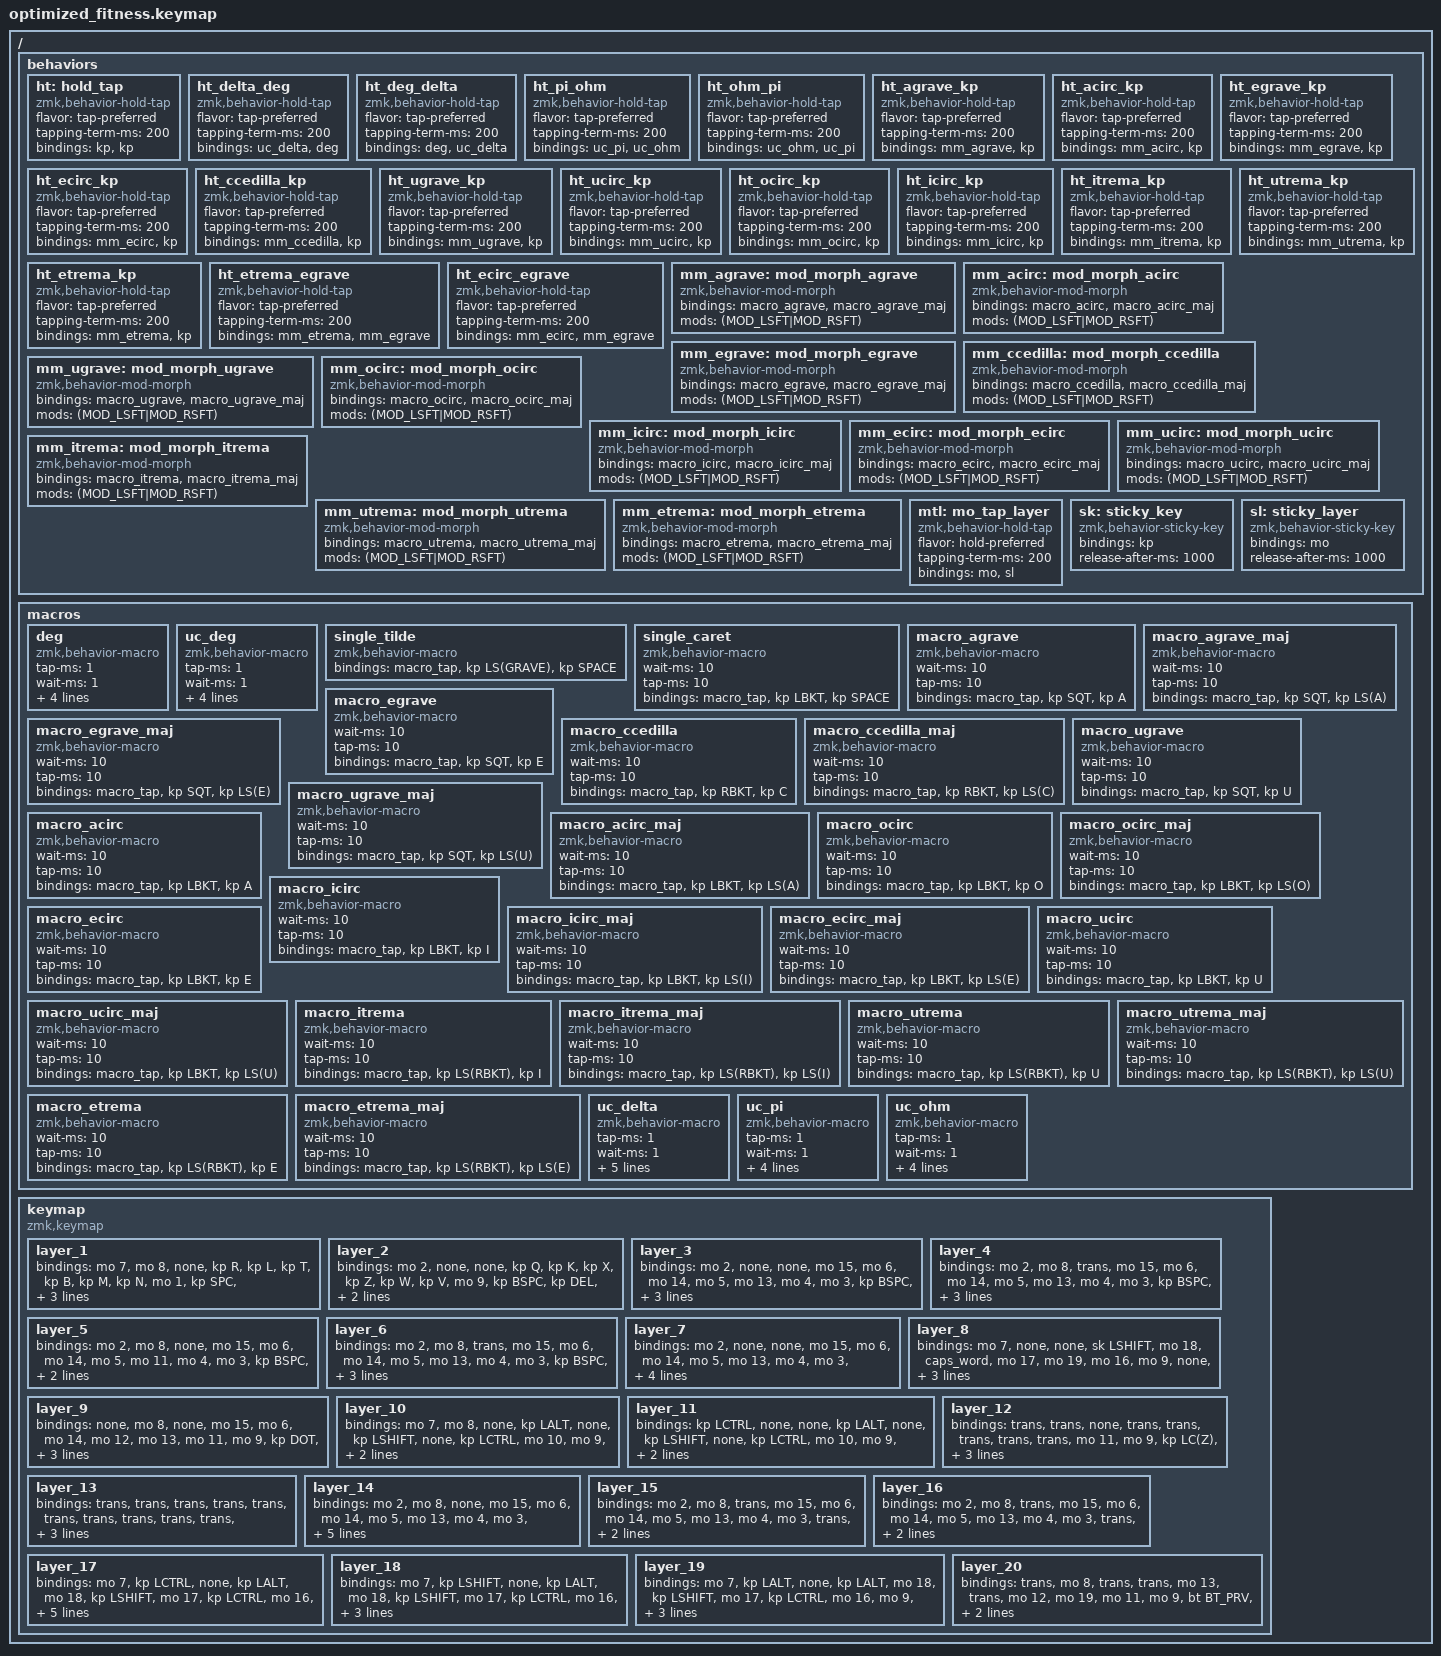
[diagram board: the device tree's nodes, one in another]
#include <behaviors.dtsi>
#include <dt-bindings/zmk/keys.h>
#include <dt-bindings/zmk/bt.h>
#include <dt-bindings/zmk/outputs.h>
#include <dt-bindings/zmk/modifiers.h>

#define DEGREE RA(NUBS)
#define EACUTE FSLH
#define CONTEXTMENU K_APP

/ {
    behaviors {
        ht: hold_tap {
            compatible = "zmk,behavior-hold-tap";
            #binding-cells = <2>;
            flavor = "tap-preferred";
            tapping-term-ms = <200>;
            bindings = <&kp &kp>;
        };

        ht_delta_deg: ht_delta_deg {
            compatible = "zmk,behavior-hold-tap";
            #binding-cells = <2>;
            flavor = "tap-preferred";
            tapping-term-ms = <200>;
            bindings = <&uc_delta &deg>;
        };

        ht_deg_delta: ht_deg_delta {
            compatible = "zmk,behavior-hold-tap";
            #binding-cells = <2>;
            flavor = "tap-preferred";
            tapping-term-ms = <200>;
            bindings = <&deg &uc_delta>;
        };

        ht_pi_ohm: ht_pi_ohm {
            compatible = "zmk,behavior-hold-tap";
            #binding-cells = <2>;
            flavor = "tap-preferred";
            tapping-term-ms = <200>;
            bindings = <&uc_pi &uc_ohm>;
        };

        ht_ohm_pi: ht_ohm_pi {
            compatible = "zmk,behavior-hold-tap";
            #binding-cells = <2>;
            flavor = "tap-preferred";
            tapping-term-ms = <200>;
            bindings = <&uc_ohm &uc_pi>;
        };

        ht_agrave_kp: ht_agrave_kp {
            compatible = "zmk,behavior-hold-tap";
            #binding-cells = <2>;
            flavor = "tap-preferred";
            tapping-term-ms = <200>;
            bindings = <&mm_agrave &kp>;
        };

        ht_acirc_kp: ht_acirc_kp {
            compatible = "zmk,behavior-hold-tap";
            #binding-cells = <2>;
            flavor = "tap-preferred";
            tapping-term-ms = <200>;
            bindings = <&mm_acirc &kp>;
        };

        ht_egrave_kp: ht_egrave_kp {
            compatible = "zmk,behavior-hold-tap";
            #binding-cells = <2>;
            flavor = "tap-preferred";
            tapping-term-ms = <200>;
            bindings = <&mm_egrave &kp>;
        };

        ht_ecirc_kp: ht_ecirc_kp {
            compatible = "zmk,behavior-hold-tap";
            #binding-cells = <2>;
            flavor = "tap-preferred";
            tapping-term-ms = <200>;
            bindings = <&mm_ecirc &kp>;
        };

        ht_ccedilla_kp: ht_ccedilla_kp {
            compatible = "zmk,behavior-hold-tap";
            #binding-cells = <2>;
            flavor = "tap-preferred";
            tapping-term-ms = <200>;
            bindings = <&mm_ccedilla &kp>;
        };

        ht_ugrave_kp: ht_ugrave_kp {
            compatible = "zmk,behavior-hold-tap";
            #binding-cells = <2>;
            flavor = "tap-preferred";
            tapping-term-ms = <200>;
            bindings = <&mm_ugrave &kp>;
        };

        ht_ucirc_kp: ht_ucirc_kp {
            compatible = "zmk,behavior-hold-tap";
            #binding-cells = <2>;
            flavor = "tap-preferred";
            tapping-term-ms = <200>;
            bindings = <&mm_ucirc &kp>;
        };

        ht_ocirc_kp: ht_ocirc_kp {
            compatible = "zmk,behavior-hold-tap";
            #binding-cells = <2>;
            flavor = "tap-preferred";
            tapping-term-ms = <200>;
            bindings = <&mm_ocirc &kp>;
        };

        ht_icirc_kp: ht_icirc_kp {
            compatible = "zmk,behavior-hold-tap";
            #binding-cells = <2>;
            flavor = "tap-preferred";
            tapping-term-ms = <200>;
            bindings = <&mm_icirc &kp>;
        };

        ht_itrema_kp: ht_itrema_kp {
            compatible = "zmk,behavior-hold-tap";
            #binding-cells = <2>;
            flavor = "tap-preferred";
            tapping-term-ms = <200>;
            bindings = <&mm_itrema &kp>;
        };

        ht_utrema_kp: ht_utrema_kp {
            compatible = "zmk,behavior-hold-tap";
            #binding-cells = <2>;
            flavor = "tap-preferred";
            tapping-term-ms = <200>;
            bindings = <&mm_utrema &kp>;
        };

        ht_etrema_kp: ht_etrema_kp {
            compatible = "zmk,behavior-hold-tap";
            #binding-cells = <2>;
            flavor = "tap-preferred";
            tapping-term-ms = <200>;
            bindings = <&mm_etrema &kp>;
        };

        ht_etrema_egrave: ht_etrema_egrave {
            compatible = "zmk,behavior-hold-tap";
            #binding-cells = <2>;
            flavor = "tap-preferred";
            tapping-term-ms = <200>;
            bindings = <&mm_etrema &mm_egrave>;
        };

        ht_ecirc_egrave: ht_ecirc_egrave {
            compatible = "zmk,behavior-hold-tap";
            #binding-cells = <2>;
            flavor = "tap-preferred";
            tapping-term-ms = <200>;
            bindings = <&mm_ecirc &mm_egrave>;
        };

        mm_agrave: mod_morph_agrave {
            compatible = "zmk,behavior-mod-morph";
            #binding-cells = <0>;
            bindings = <&macro_agrave>, <&macro_agrave_maj>;
            mods = <(MOD_LSFT|MOD_RSFT)>;
        };

        mm_acirc: mod_morph_acirc {
            compatible = "zmk,behavior-mod-morph";
            #binding-cells = <0>;
            bindings = <&macro_acirc>, <&macro_acirc_maj>;
            mods = <(MOD_LSFT|MOD_RSFT)>;
        };

        mm_egrave: mod_morph_egrave {
            compatible = "zmk,behavior-mod-morph";
            #binding-cells = <0>;
            bindings = <&macro_egrave>, <&macro_egrave_maj>;
            mods = <(MOD_LSFT|MOD_RSFT)>;
        };

        mm_ccedilla: mod_morph_ccedilla {
            compatible = "zmk,behavior-mod-morph";
            #binding-cells = <0>;
            bindings = <&macro_ccedilla>, <&macro_ccedilla_maj>;
            mods = <(MOD_LSFT|MOD_RSFT)>;
        };

        mm_ugrave: mod_morph_ugrave {
            compatible = "zmk,behavior-mod-morph";
            #binding-cells = <0>;
            bindings = <&macro_ugrave>, <&macro_ugrave_maj>;
            mods = <(MOD_LSFT|MOD_RSFT)>;
        };

        mm_ocirc: mod_morph_ocirc {
            compatible = "zmk,behavior-mod-morph";
            #binding-cells = <0>;
            bindings = <&macro_ocirc>, <&macro_ocirc_maj>;
            mods = <(MOD_LSFT|MOD_RSFT)>;
        };

        mm_icirc: mod_morph_icirc {
            compatible = "zmk,behavior-mod-morph";
            #binding-cells = <0>;
            bindings = <&macro_icirc>, <&macro_icirc_maj>;
            mods = <(MOD_LSFT|MOD_RSFT)>;
        };

        mm_ecirc: mod_morph_ecirc {
            compatible = "zmk,behavior-mod-morph";
            #binding-cells = <0>;
            bindings = <&macro_ecirc>, <&macro_ecirc_maj>;
            mods = <(MOD_LSFT|MOD_RSFT)>;
        };

        mm_ucirc: mod_morph_ucirc {
            compatible = "zmk,behavior-mod-morph";
            #binding-cells = <0>;
            bindings = <&macro_ucirc>, <&macro_ucirc_maj>;
            mods = <(MOD_LSFT|MOD_RSFT)>;
        };

        mm_itrema: mod_morph_itrema {
            compatible = "zmk,behavior-mod-morph";
            #binding-cells = <0>;
            bindings = <&macro_itrema>, <&macro_itrema_maj>;
            mods = <(MOD_LSFT|MOD_RSFT)>;
        };

        mm_utrema: mod_morph_utrema {
            compatible = "zmk,behavior-mod-morph";
            #binding-cells = <0>;
            bindings = <&macro_utrema>, <&macro_utrema_maj>;
            mods = <(MOD_LSFT|MOD_RSFT)>;
        };

        mm_etrema: mod_morph_etrema {
            compatible = "zmk,behavior-mod-morph";
            #binding-cells = <0>;
            bindings = <&macro_etrema>, <&macro_etrema_maj>;
            mods = <(MOD_LSFT|MOD_RSFT)>;
        };

        mtl: mo_tap_layer {
            compatible = "zmk,behavior-hold-tap";
            #binding-cells = <2>;
            flavor = "hold-preferred";
            tapping-term-ms = <200>;
            bindings = <&mo &sl>;
        };

        sk: sticky_key {
            compatible = "zmk,behavior-sticky-key";
            #binding-cells = <1>;
            bindings = <&kp>;
            release-after-ms = <1000>;
        };

        sl: sticky_layer {
            compatible = "zmk,behavior-sticky-key";
            #binding-cells = <1>;
            bindings = <&mo>;
            release-after-ms = <1000>;
        };
    };

    macros {
        deg: deg {
            compatible = "zmk,behavior-macro";
            #binding-cells = <0>;
            tap-ms = <1>;
            wait-ms = <1>;
            bindings = <&macro_press &kp LCTRL &kp LSHFT>
                     , <&macro_tap &kp U>
                     , <&macro_release &kp LCTRL &kp LSHFT>
                     , <&macro_tap &kp NUMBER_0 &kp NUMBER_0 &kp B &kp NUMBER_0 &kp RET>;
        };

        uc_deg: uc_deg {
            compatible = "zmk,behavior-macro";
            #binding-cells = <0>;
            tap-ms = <1>;
            wait-ms = <1>;
            bindings = <&macro_press &kp LCTRL &kp LSHFT>
                     , <&macro_tap &kp U>
                     , <&macro_release &kp LCTRL &kp LSHFT>
                     , <&macro_tap &kp NUMBER_0 &kp NUMBER_0 &kp B &kp NUMBER_0 &kp RET>;
        };

        single_tilde: single_tilde {
            compatible = "zmk,behavior-macro";
            #binding-cells = <0>;
            bindings = <&macro_tap &kp LS(GRAVE) &kp SPACE>;
        };

        single_caret: single_caret {
            compatible = "zmk,behavior-macro";
            #binding-cells = <0>;
            wait-ms = <10>;
            tap-ms = <10>;
            bindings = <&macro_tap &kp LBKT &kp SPACE>;
        };

        macro_agrave: macro_agrave {
            compatible = "zmk,behavior-macro";
            #binding-cells = <0>;
            wait-ms = <10>;
            tap-ms = <10>;
            bindings = <&macro_tap &kp SQT &kp A>;
        };

        macro_agrave_maj: macro_agrave_maj {
            compatible = "zmk,behavior-macro";
            #binding-cells = <0>;
            wait-ms = <10>;
            tap-ms = <10>;
            bindings = <&macro_tap &kp SQT &kp LS(A)>;
        };

        macro_egrave: macro_egrave {
            compatible = "zmk,behavior-macro";
            #binding-cells = <0>;
            wait-ms = <10>;
            tap-ms = <10>;
            bindings = <&macro_tap &kp SQT &kp E>;
        };

        macro_egrave_maj: macro_egrave_maj {
            compatible = "zmk,behavior-macro";
            #binding-cells = <0>;
            wait-ms = <10>;
            tap-ms = <10>;
            bindings = <&macro_tap &kp SQT &kp LS(E)>;
        };

        macro_ccedilla: macro_ccedilla {
            compatible = "zmk,behavior-macro";
            #binding-cells = <0>;
            wait-ms = <10>;
            tap-ms = <10>;
            bindings = <&macro_tap &kp RBKT &kp C>;
        };

        macro_ccedilla_maj: macro_ccedilla_maj {
            compatible = "zmk,behavior-macro";
            #binding-cells = <0>;
            wait-ms = <10>;
            tap-ms = <10>;
            bindings = <&macro_tap &kp RBKT &kp LS(C)>;
        };

        macro_ugrave: macro_ugrave {
            compatible = "zmk,behavior-macro";
            #binding-cells = <0>;
            wait-ms = <10>;
            tap-ms = <10>;
            bindings = <&macro_tap &kp SQT &kp U>;
        };

        macro_ugrave_maj: macro_ugrave_maj {
            compatible = "zmk,behavior-macro";
            #binding-cells = <0>;
            wait-ms = <10>;
            tap-ms = <10>;
            bindings = <&macro_tap &kp SQT &kp LS(U)>;
        };

        macro_acirc: macro_acirc {
            compatible = "zmk,behavior-macro";
            #binding-cells = <0>;
            wait-ms = <10>;
            tap-ms = <10>;
            bindings = <&macro_tap &kp LBKT &kp A>;
        };

        macro_acirc_maj: macro_acirc_maj {
            compatible = "zmk,behavior-macro";
            #binding-cells = <0>;
            wait-ms = <10>;
            tap-ms = <10>;
            bindings = <&macro_tap &kp LBKT &kp LS(A)>;
        };

        macro_ocirc: macro_ocirc {
            compatible = "zmk,behavior-macro";
            #binding-cells = <0>;
            wait-ms = <10>;
            tap-ms = <10>;
            bindings = <&macro_tap &kp LBKT &kp O>;
        };

        macro_ocirc_maj: macro_ocirc_maj {
            compatible = "zmk,behavior-macro";
            #binding-cells = <0>;
            wait-ms = <10>;
            tap-ms = <10>;
            bindings = <&macro_tap &kp LBKT &kp LS(O)>;
        };

        macro_icirc: macro_icirc {
            compatible = "zmk,behavior-macro";
            #binding-cells = <0>;
            wait-ms = <10>;
            tap-ms = <10>;
            bindings = <&macro_tap &kp LBKT &kp I>;
        };

        macro_icirc_maj: macro_icirc_maj {
            compatible = "zmk,behavior-macro";
            #binding-cells = <0>;
            wait-ms = <10>;
            tap-ms = <10>;
            bindings = <&macro_tap &kp LBKT &kp LS(I)>;
        };

        macro_ecirc: macro_ecirc {
            compatible = "zmk,behavior-macro";
            #binding-cells = <0>;
            wait-ms = <10>;
            tap-ms = <10>;
            bindings = <&macro_tap &kp LBKT &kp E>;
        };

        macro_ecirc_maj: macro_ecirc_maj {
            compatible = "zmk,behavior-macro";
            #binding-cells = <0>;
            wait-ms = <10>;
            tap-ms = <10>;
            bindings = <&macro_tap &kp LBKT &kp LS(E)>;
        };

        macro_ucirc: macro_ucirc {
            compatible = "zmk,behavior-macro";
            #binding-cells = <0>;
            wait-ms = <10>;
            tap-ms = <10>;
            bindings = <&macro_tap &kp LBKT &kp U>;
        };

        macro_ucirc_maj: macro_ucirc_maj {
            compatible = "zmk,behavior-macro";
            #binding-cells = <0>;
            wait-ms = <10>;
            tap-ms = <10>;
            bindings = <&macro_tap &kp LBKT &kp LS(U)>;
        };

        macro_itrema: macro_itrema {
            compatible = "zmk,behavior-macro";
            #binding-cells = <0>;
            wait-ms = <10>;
            tap-ms = <10>;
            bindings = <&macro_tap &kp LS(RBKT) &kp I>;
        };

        macro_itrema_maj: macro_itrema_maj {
            compatible = "zmk,behavior-macro";
            #binding-cells = <0>;
            wait-ms = <10>;
            tap-ms = <10>;
            bindings = <&macro_tap &kp LS(RBKT) &kp LS(I)>;
        };

        macro_utrema: macro_utrema {
            compatible = "zmk,behavior-macro";
            #binding-cells = <0>;
            wait-ms = <10>;
            tap-ms = <10>;
            bindings = <&macro_tap &kp LS(RBKT) &kp U>;
        };

        macro_utrema_maj: macro_utrema_maj {
            compatible = "zmk,behavior-macro";
            #binding-cells = <0>;
            wait-ms = <10>;
            tap-ms = <10>;
            bindings = <&macro_tap &kp LS(RBKT) &kp LS(U)>;
        };

        macro_etrema: macro_etrema {
            compatible = "zmk,behavior-macro";
            #binding-cells = <0>;
            wait-ms = <10>;
            tap-ms = <10>;
            bindings = <&macro_tap &kp LS(RBKT) &kp E>;
        };

        macro_etrema_maj: macro_etrema_maj {
            compatible = "zmk,behavior-macro";
            #binding-cells = <0>;
            wait-ms = <10>;
            tap-ms = <10>;
            bindings = <&macro_tap &kp LS(RBKT) &kp LS(E)>;
        };

        uc_delta: uc_delta {
            compatible = "zmk,behavior-macro";
            #binding-cells = <0>;
            tap-ms = <1>;
            wait-ms = <1>;
            bindings = <&macro_press &kp LCTRL &kp LSHFT>
                     , <&macro_tap &kp U>
                     , <&macro_release &kp LCTRL &kp LSHFT>
                     , <&macro_tap &kp NUMBER_0 &kp NUMBER_3 &kp NUMBER_9 &kp NUMBER_4 &kp RET>;
        };

        uc_pi: uc_pi {
            compatible = "zmk,behavior-macro";
            #binding-cells = <0>;
            tap-ms = <1>;
            wait-ms = <1>;
            bindings = <&macro_press &kp LCTRL &kp LSHFT>
                     , <&macro_tap &kp U>
                     , <&macro_release &kp LCTRL &kp LSHFT>
                     , <&macro_tap &kp NUMBER_0 &kp NUMBER_3 &kp C &kp NUMBER_0 &kp RET>;
        };

        uc_ohm: uc_ohm {
            compatible = "zmk,behavior-macro";
            #binding-cells = <0>;
            tap-ms = <1>;
            wait-ms = <1>;
            bindings = <&macro_press &kp LCTRL &kp LSHFT>
                     , <&macro_tap &kp U>
                     , <&macro_release &kp LCTRL &kp LSHFT>
                     , <&macro_tap &kp NUMBER_0 &kp NUMBER_3 &kp A &kp NUMBER_9 &kp RET>;
        };
    };
    keymap {
        compatible = "zmk,keymap";

        layer_1 {
            bindings = <
                // Left hand (Index 1 to 10)
                &mo 7                      // 1
                &mo 8                      // 2
                &none                      // 3
                &kp R                      // 4
                &kp L                      // 5
                &kp T                      // 6
                &kp B                      // 7
                &kp M                      // 8
                &kp N                      // 9
                &mo 1                      // 10

                // Right hand (Index 11 to 20)
                &kp SPC                    // 11
                &ht_ugrave_kp 0 U          // 12
                &none                      // 13
                &ht_ccedilla_kp 0 C        // 14
                &ht FSLH E                 // 15
                &kp S                      // 16
                &ht_ocirc_kp 0 O           // 17
                &kp D                      // 18
                &ht_icirc_kp 0 I           // 19
                &ht_agrave_kp 0 A          // 20
            >;
        };

        layer_2 {
            bindings = <
                // Left hand (Index 1 to 10)
                &mo 2                      // 1
                &none                      // 2
                &none                      // 3
                &kp Q                      // 4
                &kp K                      // 5
                &kp X                      // 6
                &kp Z                      // 7
                &kp W                      // 8
                &kp V                      // 9
                &mo 9                      // 10

                // Right hand (Index 11 to 20)
                &kp BSPC                   // 11
                &kp DEL                    // 12
                &none                      // 13
                &kp P                      // 14
                &kp F                      // 15
                &kp H                      // 16
                &kp J                      // 17
                &kp G                      // 18
                &kp Y                      // 19
                &kp RET                    // 20
            >;
        };

        layer_3 {
            bindings = <
                // Left hand (Index 1 to 10)
                &mo 2                      // 1
                &none                      // 2
                &none                      // 3
                &mo 15                     // 4
                &mo 6                      // 5
                &mo 14                     // 6
                &mo 5                      // 7
                &mo 13                     // 8
                &mo 4                      // 9
                &mo 3                      // 10

                // Right hand (Index 11 to 20)
                &kp BSPC                   // 11
                &kp DOT                    // 12
                &none                      // 13
                &kp NUMBER_1               // 14
                &kp NUMBER_4               // 15
                &kp NUMBER_2               // 16
                &kp NUMBER_5               // 17
                &kp NUMBER_3               // 18
                &kp NUMBER_6               // 19
                &kp RET                    // 20
            >;
        };

        layer_4 {
            bindings = <
                // Left hand (Index 1 to 10)
                &mo 2                      // 1
                &mo 8                      // 2
                &trans                     // 3
                &mo 15                     // 4
                &mo 6                      // 5
                &mo 14                     // 6
                &mo 5                      // 7
                &mo 13                     // 8
                &mo 4                      // 9
                &mo 3                      // 10

                // Right hand (Index 11 to 20)
                &kp BSPC                   // 11
                &kp NUMBER_0               // 12
                &trans                     // 13
                &kp NUMBER_7               // 14
                &none                      // 15
                &kp NUMBER_8               // 16
                &kp DOT                    // 17
                &kp NUMBER_9               // 18
                &none                      // 19
                &kp RET                    // 20
            >;
        };

        layer_5 {
            bindings = <
                // Left hand (Index 1 to 10)
                &mo 2                      // 1
                &mo 8                      // 2
                &none                      // 3
                &mo 15                     // 4
                &mo 6                      // 5
                &mo 14                     // 6
                &mo 5                      // 7
                &mo 11                     // 8
                &mo 4                      // 9
                &mo 3                      // 10

                // Right hand (Index 11 to 20)
                &kp BSPC                   // 11
                &kp DOT                    // 12
                &none                      // 13
                &kp A                      // 14
                &kp LS(D)                  // 15
                &kp B                      // 16
                &kp E                      // 17
                &kp C                      // 18
                &kp F                      // 19
                &kp RET                    // 20
            >;
        };

        layer_6 {
            bindings = <
                // Left hand (Index 1 to 10)
                &mo 2                      // 1
                &mo 8                      // 2
                &trans                     // 3
                &mo 15                     // 4
                &mo 6                      // 5
                &mo 14                     // 6
                &mo 5                      // 7
                &mo 13                     // 8
                &mo 4                      // 9
                &mo 3                      // 10

                // Right hand (Index 11 to 20)
                &kp BSPC                   // 11
                &none                      // 12
                &trans                     // 13
                &kp LS(EQUAL)              // 14
                &kp MINUS                  // 15
                &kp LS(NUMBER_8)           // 16
                &kp LS(NUMBER_3)           // 17
                &kp LBKT                   // 18
                &kp EQUAL                  // 19
                &kp RET                    // 20
            >;
        };

        layer_7 {
            bindings = <
                // Left hand (Index 1 to 10)
                &mo 2                      // 1
                &none                      // 2
                &none                      // 3
                &mo 15                     // 4
                &mo 6                      // 5
                &mo 14                     // 6
                &mo 5                      // 7
                &mo 13                     // 8
                &mo 4                      // 9
                &mo 3                      // 10

                // Right hand (Index 11 to 20)
                &kp LS(NUMBER_9)           // 11
                &kp LS(NUMBER_0)           // 12
                &none                      // 13
                &kp RA(SQT)                // 14
                &kp RA(BSLH)               // 15
                &kp RA(LBKT)               // 16
                &kp RA(RBKT)               // 17
                &kp BSLH                   // 18
                &kp LS(BSLH)               // 19
                &kp LS(NUMBER_2)           // 20
            >;
        };

        layer_8 {
            bindings = <
                // Left hand (Index 1 to 10)
                &mo 7                      // 1
                &none                      // 2
                &none                      // 3
                &sk LSHIFT                 // 4
                &mo 18                     // 5
                &caps_word                 // 6
                &mo 17                     // 7
                &mo 19                     // 8
                &mo 16                     // 9
                &mo 9                      // 10

                // Right hand (Index 11 to 20)
                &none                      // 11
                &mm_ucirc                  // 12
                &none                      // 13
                &mm_ecirc                  // 14
                &ht_etrema_egrave 0 0      // 15
                &none                      // 16
                &mm_itrema                 // 17
                &none                      // 18
                &none                      // 19
                &mm_acirc                  // 20
            >;
        };

        layer_9 {
            bindings = <
                // Left hand (Index 1 to 10)
                &none                      // 1
                &mo 8                      // 2
                &none                      // 3
                &mo 15                     // 4
                &mo 6                      // 5
                &mo 14                     // 6
                &mo 12                     // 7
                &mo 13                     // 8
                &mo 11                     // 9
                &mo 9                      // 10

                // Right hand (Index 11 to 20)
                &kp DOT                    // 11
                &kp COMMA                  // 12
                &none                      // 13
                &kp LS(COMMA)              // 14
                &kp MINUS                  // 15
                &kp SEMI                   // 16
                &kp LS(SEMI)               // 17
                &kp LS(NUMBER_1)           // 18
                &kp LS(NUMBER_6)           // 19
                &kp LS(MINUS)              // 20
            >;
        };

        layer_10 {
            bindings = <
                // Left hand (Index 1 to 10)
                &mo 7                      // 1
                &mo 8                      // 2
                &none                      // 3
                &kp LALT                   // 4
                &none                      // 5
                &kp LSHIFT                 // 6
                &none                      // 7
                &kp LCTRL                  // 8
                &mo 10                     // 9
                &mo 9                      // 10

                // Right hand (Index 11 to 20)
                &kp LEFT                   // 11
                &kp RIGHT                  // 12
                &none                      // 13
                &kp UP                     // 14
                &kp DOWN                   // 15
                &kp K_APP                  // 16
                &none                      // 17
                &kp ESC                    // 18
                &kp TAB                    // 19
                &kp RET                    // 20
            >;
        };

        layer_11 {
            bindings = <
                // Left hand (Index 1 to 10)
                &kp LCTRL                  // 1
                &none                      // 2
                &none                      // 3
                &kp LALT                   // 4
                &none                      // 5
                &kp LSHIFT                 // 6
                &none                      // 7
                &kp LCTRL                  // 8
                &mo 10                     // 9
                &mo 9                      // 10

                // Right hand (Index 11 to 20)
                &kp HOME                   // 11
                &kp END                    // 12
                &trans                     // 13
                &kp PG_UP                  // 14
                &kp PG_DN                  // 15
                &kp K_APP                  // 16
                &none                      // 17
                &kp ESC                    // 18
                &kp TAB                    // 19
                &kp RET                    // 20
            >;
        };

        layer_12 {
            bindings = <
                // Left hand (Index 1 to 10)
                &trans                     // 1
                &trans                     // 2
                &none                      // 3
                &trans                     // 4
                &trans                     // 5
                &trans                     // 6
                &trans                     // 7
                &trans                     // 8
                &mo 11                     // 9
                &mo 9                      // 10

                // Right hand (Index 11 to 20)
                &kp LC(Z)                  // 11
                &kp LC(S)                  // 12
                &trans                     // 13
                &kp LC(C)                  // 14
                &kp LC(A)                  // 15
                &kp LC(V)                  // 16
                &kp LC(F)                  // 17
                &kp LC(X)                  // 18
                &kp LC(H)                  // 19
                &kp LC(Y)                  // 20
            >;
        };

        layer_13 {
            bindings = <
                // Left hand (Index 1 to 10)
                &trans                     // 1
                &trans                     // 2
                &trans                     // 3
                &trans                     // 4
                &trans                     // 5
                &trans                     // 6
                &trans                     // 7
                &trans                     // 8
                &trans                     // 9
                &trans                     // 10

                // Right hand (Index 11 to 20)
                &kp LC(LS(T))              // 11
                &kp LC(LS(S))              // 12
                &trans                     // 13
                &trans                     // 14
                &trans                     // 15
                &trans                     // 16
                &trans                     // 17
                &kp LC(LA(DEL))            // 18
                &trans                     // 19
                &trans                     // 20
            >;
        };

        layer_14 {
            bindings = <
                // Left hand (Index 1 to 10)
                &mo 2                      // 1
                &mo 8                      // 2
                &none                      // 3
                &mo 15                     // 4
                &mo 6                      // 5
                &mo 14                     // 6
                &mo 5                      // 7
                &mo 13                     // 8
                &mo 4                      // 9
                &mo 3                      // 10

                // Right hand (Index 11 to 20)
                &ht SEMI LS(SEMI)          // 11
                &ht DOT COMMA              // 12
                &ht_delta_deg 0 0          // 13
                &kp GRAVE                  // 14
                &kp LS(NUMBER_5)           // 15
                &kp RA(NUMBER_2)           // 16
                &kp RA(NUMBER_1)           // 17
                &kp LS(NUMBER_4)           // 18
                &single_tilde              // 19
                &ht LS(DOT) RA(NUMBER_3)   // 20
            >;
        };

        layer_15 {
            bindings = <
                // Left hand (Index 1 to 10)
                &mo 2                      // 1
                &mo 8                      // 2
                &trans                     // 3
                &mo 15                     // 4
                &mo 6                      // 5
                &mo 14                     // 6
                &mo 5                      // 7
                &mo 13                     // 8
                &mo 4                      // 9
                &mo 3                      // 10

                // Right hand (Index 11 to 20)
                &trans                     // 11
                &trans                     // 12
                &trans                     // 13
                &trans                     // 14
                &trans                     // 15
                &trans                     // 16
                &trans                     // 17
                &trans                     // 18
                &trans                     // 19
                &trans                     // 20
            >;
        };

        layer_16 {
            bindings = <
                // Left hand (Index 1 to 10)
                &mo 2                      // 1
                &mo 8                      // 2
                &trans                     // 3
                &mo 15                     // 4
                &mo 6                      // 5
                &mo 14                     // 6
                &mo 5                      // 7
                &mo 13                     // 8
                &mo 4                      // 9
                &mo 3                      // 10

                // Right hand (Index 11 to 20)
                &trans                     // 11
                &trans                     // 12
                &trans                     // 13
                &trans                     // 14
                &trans                     // 15
                &trans                     // 16
                &trans                     // 17
                &trans                     // 18
                &trans                     // 19
                &trans                     // 20
            >;
        };

        layer_17 {
            bindings = <
                // Left hand (Index 1 to 10)
                &mo 7                      // 1
                &kp LCTRL                  // 2
                &none                      // 3
                &kp LALT                   // 4
                &mo 18                     // 5
                &kp LSHIFT                 // 6
                &mo 17                     // 7
                &kp LCTRL                  // 8
                &mo 16                     // 9
                &mo 9                      // 10

                // Right hand (Index 11 to 20)
                &kp LG(NUMBER_1)           // 11
                &kp LG(NUMBER_2)           // 12
                &none                      // 13
                &kp LG(NUMBER_3)           // 14
                &kp LG(NUMBER_4)           // 15
                &kp LG(NUMBER_5)           // 16
                &kp LG(NUMBER_6)           // 17
                &kp LG(NUMBER_7)           // 18
                &kp LG(NUMBER_8)           // 19
                &kp LG(NUMBER_9)           // 20
            >;
        };

        layer_18 {
            bindings = <
                // Left hand (Index 1 to 10)
                &mo 7                      // 1
                &kp LSHIFT                 // 2
                &none                      // 3
                &kp LALT                   // 4
                &mo 18                     // 5
                &kp LSHIFT                 // 6
                &mo 17                     // 7
                &kp LCTRL                  // 8
                &mo 16                     // 9
                &mo 9                      // 10

                // Right hand (Index 11 to 20)
                &kp LG(LEFT)               // 11
                &kp LG(RIGHT)              // 12
                &none                      // 13
                &kp LG(UP)                 // 14
                &kp LG(DOWN)               // 15
                &kp LG(F)                  // 16
                &kp LG(O)                  // 17
                &kp LG(W)                  // 18
                &kp LG(J)                  // 19
                &kp LG(K)                  // 20
            >;
        };

        layer_19 {
            bindings = <
                // Left hand (Index 1 to 10)
                &mo 7                      // 1
                &kp LALT                   // 2
                &none                      // 3
                &kp LALT                   // 4
                &mo 18                     // 5
                &kp LSHIFT                 // 6
                &mo 17                     // 7
                &kp LCTRL                  // 8
                &mo 16                     // 9
                &mo 9                      // 10

                // Right hand (Index 11 to 20)
                &kp LG(SPC)                // 11
                &kp LG(Q)                  // 12
                &none                      // 13
                &kp LG(S)                  // 14
                &kp LG(L)                  // 15
                &kp LG(EQUAL)              // 16
                &kp LG(MINUS)              // 17
                &kp LG(ESC)                // 18
                &kp LG(TAB)                // 19
                &kp LG(RET)                // 20
            >;
        };

        layer_20 {
            bindings = <
                // Left hand (Index 1 to 10)
                &trans                     // 1
                &mo 8                      // 2
                &trans                     // 3
                &trans                     // 4
                &mo 13                     // 5
                &trans                     // 6
                &mo 12                     // 7
                &mo 19                     // 8
                &mo 11                     // 9
                &mo 9                      // 10

                // Right hand (Index 11 to 20)
                &bt BT_PRV                 // 11
                &bt BT_NXT                 // 12
                &mo 8                      // 13
                &bt BT_CLR_ALL             // 14
                &bt BT_CLR                 // 15
                &trans                     // 16
                &trans                     // 17
                &trans                     // 18
                &trans                     // 19
                &trans                     // 20
            >;
        };

    };
};
